AUTOSAR XML (schema 4-3-0)
package /ComponentTypes
  swc implementation YDF_BootloaderHandler_Implementation: behavior=YDF_BootloaderHandler_InternalBehavior
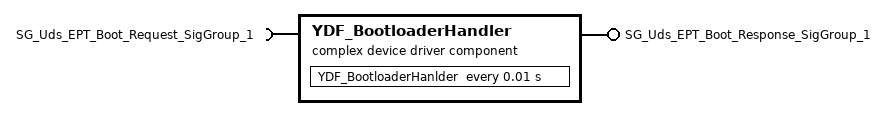
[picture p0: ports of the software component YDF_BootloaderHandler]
  complex device driver sw component type YDF_BootloaderHandler
    require port SG_Uds_EPT_Boot_Request_SigGroup_1: nonqueued-receiver-com-spec{data-element=SG_Uds_EPT_Boot_Request_SigGroup, filter=data-filter-type=ALWAYS, init-value=fields=[UDS_EPT_BootCmd1:0, UDS_EPT_BootCmd2:0, UDS_EPT_BootCmd3:0]}, required-interface=SG_Uds_EPT_Boot_Request_SigGroup_1
    provide port SG_Uds_EPT_Boot_Response_SigGroup_1: nonqueued-sender-com-spec{data-element=SG_Uds_EPT_Boot_Response_SigGroup, init-value=fields=[Uds_EPT_bootResponse_Byte0:0, Uds_EPT_bootResponse_Byte1:0, Uds_EPT_bootResponse_Byte2:0, Uds_EPT_bootResponse_Byte3:0, Uds_EPT_bootResponse_Byte4:0, Uds_EPT_bootResponse_Byte5:0, Uds_EPT_bootResponse_Byte6:0, Uds_EPT_bootResponse_Byte7:0]}, provided-interface=SG_Uds_EPT_Boot_Response_SigGroup_1
    behavior YDF_BootloaderHandler_InternalBehavior
      timing event TMT_YDF_BootloaderHanlder: start-on-event=YDF_BootloaderHanlder, period=0.01
      runnable YDF_BootloaderHanlder
